AUTOSAR XML (schema 4-0-3)
standard types defined: Boolean, UInt16, UInt32
package /AUTOSAR_Platform/DataConstrs
  range DC_Boolean: raw 0..1
  range DC_UInt16: raw 0..65535
package /PATAC/Facility/DataTypes/Implementation
  compu method COMPU_Boolean: 0=FALSE, 1=TRUE
  unit NoUnit: factor-si-to-unit=1, offset-si-to-unit=0
package /PATAC/MSM/ComponentTypes
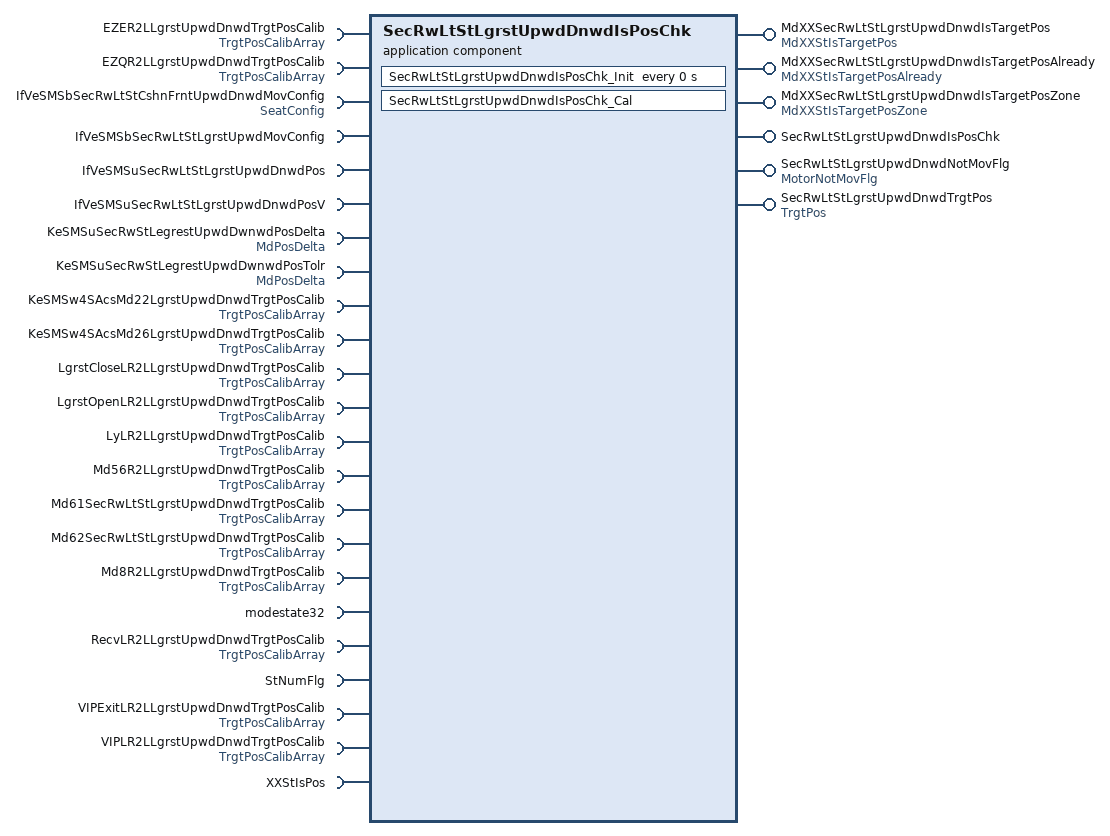
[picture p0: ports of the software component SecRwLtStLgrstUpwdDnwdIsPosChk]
  application sw component type SecRwLtStLgrstUpwdDnwdIsPosChk
    6 x provide port:
      MdXXSecRwLtStLgrstUpwdDnwdIsTargetPos: nonqueued-sender-com-spec=data-element=MdXXStIsTargetPos/Val, provided-interface=MdXXStIsTargetPos
      MdXXSecRwLtStLgrstUpwdDnwdIsTargetPosAlready: nonqueued-sender-com-spec=data-element=MdXXStIsTargetPosAlready/Val, provided-interface=MdXXStIsTargetPosAlready
      MdXXSecRwLtStLgrstUpwdDnwdIsTargetPosZone: nonqueued-sender-com-spec=data-element=MdXXStIsTargetPosZone/Val, provided-interface=MdXXStIsTargetPosZone
      SecRwLtStLgrstUpwdDnwdIsPosChk: server-com-spec{operation=Cal, queue-length=1}, provided-interface=SecRwLtStLgrstUpwdDnwdIsPosChk
      SecRwLtStLgrstUpwdDnwdNotMovFlg: nonqueued-sender-com-spec{data-element=MotorNotMovFlg/Val, init-value=0}, provided-interface=MotorNotMovFlg
      SecRwLtStLgrstUpwdDnwdTrgtPos: nonqueued-sender-com-spec{data-element=TrgtPos/Val, init-value=4095}, provided-interface=TrgtPos
    23 x require port:
      EZER2LLgrstUpwdDnwdTrgtPosCalib: nonqueued-receiver-com-spec{data-element=TrgtPosArray, filter=data-filter-type=ALWAYS, init-value=[4095, 4095, 4095]}, required-interface=TrgtPosCalibArray
      EZQR2LLgrstUpwdDnwdTrgtPosCalib: nonqueued-receiver-com-spec{data-element=TrgtPosArray, filter=data-filter-type=ALWAYS, init-value=[4095, 4095, 4095]}, required-interface=TrgtPosCalibArray
      IfVeSMSbSecRwLtStCshnFrntUpwdDnwdMovConfig: nonqueued-receiver-com-spec{data-element=SeatConfig/Val, filter=data-filter-type=ALWAYS, init-value=0}, required-interface=SeatConfig
      IfVeSMSbSecRwLtStLgrstUpwdMovConfig: nonqueued-receiver-com-spec{data-element=IfVeSMSbSecRwLtStLgrstUpwdMovConfig/Val, filter=data-filter-type=ALWAYS, init-value=0}, required-interface=IfVeSMSbSecRwLtStLgrstUpwdMovConfig
      IfVeSMSuSecRwLtStLgrstUpwdDnwdPos: nonqueued-receiver-com-spec{data-element=IfVeSMSuSecRwLtStLgrstUpwdDnwdPos/Val, filter=data-filter-type=ALWAYS, init-value=0}, required-interface=IfVeSMSuSecRwLtStLgrstUpwdDnwdPos
      IfVeSMSuSecRwLtStLgrstUpwdDnwdPosV: nonqueued-receiver-com-spec{data-element=IfVeSMSuSecRwLtStLgrstUpwdDnwdPosV/Val, filter=data-filter-type=ALWAYS, init-value=0}, required-interface=IfVeSMSuSecRwLtStLgrstUpwdDnwdPosV
      KeSMSuSecRwStLegrestUpwdDwnwdPosDelta: parameter-require-com-spec{init-value=150, parameter=Val}, required-interface=MdPosDelta
      KeSMSuSecRwStLegrestUpwdDwnwdPosTolr: parameter-require-com-spec{init-value=150, parameter=Val}, required-interface=MdPosDelta
      KeSMSw4SAcsMd22LgrstUpwdDnwdTrgtPosCalib: nonqueued-receiver-com-spec{data-element=TrgtPosArray, filter=data-filter-type=ALWAYS, init-value=[4095, 4095, 4095]}, required-interface=TrgtPosCalibArray
      KeSMSw4SAcsMd26LgrstUpwdDnwdTrgtPosCalib: nonqueued-receiver-com-spec{data-element=TrgtPosArray, filter=data-filter-type=ALWAYS, init-value=[4095, 4095, 4095]}, required-interface=TrgtPosCalibArray
      LgrstCloseLR2LLgrstUpwdDnwdTrgtPosCalib: nonqueued-receiver-com-spec{data-element=TrgtPosArray, filter=data-filter-type=ALWAYS, init-value=[4095, 4095, 4095]}, required-interface=TrgtPosCalibArray
      LgrstOpenLR2LLgrstUpwdDnwdTrgtPosCalib: nonqueued-receiver-com-spec{data-element=TrgtPosArray, filter=data-filter-type=ALWAYS, init-value=[4095, 4095, 4095]}, required-interface=TrgtPosCalibArray
      LyLR2LLgrstUpwdDnwdTrgtPosCalib: nonqueued-receiver-com-spec{data-element=TrgtPosArray, filter=data-filter-type=ALWAYS, init-value=[4095, 4095, 4095]}, required-interface=TrgtPosCalibArray
      Md56R2LLgrstUpwdDnwdTrgtPosCalib: nonqueued-receiver-com-spec{data-element=TrgtPosArray, filter=data-filter-type=ALWAYS, init-value=[4095, 4095, 4095]}, required-interface=TrgtPosCalibArray
      Md61SecRwLtStLgrstUpwdDnwdTrgtPosCalib: nonqueued-receiver-com-spec{data-element=TrgtPosArray, filter=data-filter-type=ALWAYS, init-value=[4095, 4095, 4095]}, required-interface=TrgtPosCalibArray
      Md62SecRwLtStLgrstUpwdDnwdTrgtPosCalib: nonqueued-receiver-com-spec{data-element=TrgtPosArray, filter=data-filter-type=ALWAYS, init-value=[4095, 4095, 4095]}, required-interface=TrgtPosCalibArray
      Md8R2LLgrstUpwdDnwdTrgtPosCalib: nonqueued-receiver-com-spec{data-element=TrgtPosArray, filter=data-filter-type=ALWAYS, init-value=[4095, 4095, 4095]}, required-interface=TrgtPosCalibArray
      modestate32: nonqueued-receiver-com-spec{data-element=modestate32/Val, filter=data-filter-type=ALWAYS, init-value=0}, required-interface=modestate32
      RecvLR2LLgrstUpwdDnwdTrgtPosCalib: nonqueued-receiver-com-spec{data-element=TrgtPosArray, filter=data-filter-type=ALWAYS, init-value=[4095, 4095, 4095]}, required-interface=TrgtPosCalibArray
      StNumFlg: required-interface=StNumFlg
        required-com-specs:
          data-element=Is4s, filter=data-filter-type=ALWAYS, init-value=0
          data-element=Is6s, filter=data-filter-type=ALWAYS, init-value=0
          data-element=Is6s7s, filter=data-filter-type=ALWAYS, init-value=0
          data-element=Is7s, filter=data-filter-type=ALWAYS, init-value=0
      VIPExitLR2LLgrstUpwdDnwdTrgtPosCalib: nonqueued-receiver-com-spec{data-element=TrgtPosArray, filter=data-filter-type=ALWAYS, init-value=[4095, 4095, 4095]}, required-interface=TrgtPosCalibArray
      VIPLR2LLgrstUpwdDnwdTrgtPosCalib: nonqueued-receiver-com-spec{data-element=TrgtPosArray, filter=data-filter-type=ALWAYS, init-value=[4095, 4095, 4095]}, required-interface=TrgtPosCalibArray
      XXStIsPos: client-com-spec=Get, required-interface=XXStIsPos
    behavior SecRwLtStLgrstUpwdDnwdIsPosChk_InternalBehavior
      operation invoked event OIT_SecRwLtStLgrstUpwdDnwdIsPosChk_Cal_SecRwLtStLgrstUpwdDnwdIsPosChk_Cal: start-on-event=SecRwLtStLgrstUpwdDnwdIsPosChk_Cal, operation=SecRwLtStLgrstUpwdDnwdIsPosChk.Cal
      timing event SecRwLtStLgrstUpwdDnwdIsPosChk_InitEvent: start-on-event=SecRwLtStLgrstUpwdDnwdIsPosChk_Init, period=0
      runnable SecRwLtStLgrstUpwdDnwdIsPosChk_Cal
        data-receive-point-by-arguments:
          23 x access:
            REC_EZER2LLgrstUpwdDnwdTrgtPosCalib_TrgtPosArray: accessed-variable=EZER2LLgrstUpwdDnwdTrgtPosCalib.TrgtPosArray
            REC_EZQR2LLgrstUpwdDnwdTrgtPosCalib_TrgtPosArray: accessed-variable=EZQR2LLgrstUpwdDnwdTrgtPosCalib.TrgtPosArray
            REC_IfVeSMSbSecRwLtStCshnFrntUpwdDnwdMovConfig_Val: accessed-variable=IfVeSMSbSecRwLtStCshnFrntUpwdDnwdMovConfig.Val
            REC_IfVeSMSbSecRwLtStLgrstUpwdMovConfig_Val: accessed-variable=IfVeSMSbSecRwLtStLgrstUpwdMovConfig.Val
            REC_IfVeSMSuSecRwLtStLgrstUpwdDnwdPos_Val: accessed-variable=IfVeSMSuSecRwLtStLgrstUpwdDnwdPos.Val
            REC_IfVeSMSuSecRwLtStLgrstUpwdDnwdPosV_Val: accessed-variable=IfVeSMSuSecRwLtStLgrstUpwdDnwdPosV.Val
            REC_KeSMSw4SAcsMd22LgrstUpwdDnwdTrgtPosCalib_TrgtPosArray: accessed-variable=KeSMSw4SAcsMd22LgrstUpwdDnwdTrgtPosCalib.TrgtPosArray
            REC_KeSMSw4SAcsMd26LgrstUpwdDnwdTrgtPosCalib_TrgtPosArray: accessed-variable=KeSMSw4SAcsMd26LgrstUpwdDnwdTrgtPosCalib.TrgtPosArray
            REC_LgrstCloseLR2LLgrstUpwdDnwdTrgtPosCalib_TrgtPosArray: accessed-variable=LgrstCloseLR2LLgrstUpwdDnwdTrgtPosCalib.TrgtPosArray
            REC_LgrstOpenLR2LLgrstUpwdDnwdTrgtPosCalib_TrgtPosArray: accessed-variable=LgrstOpenLR2LLgrstUpwdDnwdTrgtPosCalib.TrgtPosArray
            REC_LyLR2LLgrstUpwdDnwdTrgtPosCalib_TrgtPosArray: accessed-variable=LyLR2LLgrstUpwdDnwdTrgtPosCalib.TrgtPosArray
            REC_Md56R2LLgrstUpwdDnwdTrgtPosCalib_TrgtPosArray: accessed-variable=Md56R2LLgrstUpwdDnwdTrgtPosCalib.TrgtPosArray
            REC_Md61SecRwLtStLgrstUpwdDnwdTrgtPosCalib_TrgtPosArray: accessed-variable=Md61SecRwLtStLgrstUpwdDnwdTrgtPosCalib.TrgtPosArray
            REC_Md62SecRwLtStLgrstUpwdDnwdTrgtPosCalib_TrgtPosArray: accessed-variable=Md62SecRwLtStLgrstUpwdDnwdTrgtPosCalib.TrgtPosArray
            REC_Md8R2LLgrstUpwdDnwdTrgtPosCalib_TrgtPosArray: accessed-variable=Md8R2LLgrstUpwdDnwdTrgtPosCalib.TrgtPosArray
            REC_modestate32_Val: accessed-variable=modestate32.Val
            REC_RecvLR2LLgrstUpwdDnwdTrgtPosCalib_TrgtPosArray: accessed-variable=RecvLR2LLgrstUpwdDnwdTrgtPosCalib.TrgtPosArray
            REC_StNumFlg_Is4s: accessed-variable=StNumFlg.Is4s
            REC_StNumFlg_Is6s: accessed-variable=StNumFlg.Is6s
            REC_StNumFlg_Is6s7s: accessed-variable=StNumFlg.Is6s7s
            REC_StNumFlg_Is7s: accessed-variable=StNumFlg.Is7s
            REC_VIPExitLR2LLgrstUpwdDnwdTrgtPosCalib_TrgtPosArray: accessed-variable=VIPExitLR2LLgrstUpwdDnwdTrgtPosCalib.TrgtPosArray
            REC_VIPLR2LLgrstUpwdDnwdTrgtPosCalib_TrgtPosArray: accessed-variable=VIPLR2LLgrstUpwdDnwdTrgtPosCalib.TrgtPosArray
        data-send-points:
          5 x access:
            SEND_MdXXSecRwLtStLgrstUpwdDnwdIsTargetPos_Val: accessed-variable=MdXXSecRwLtStLgrstUpwdDnwdIsTargetPos.Val
            SEND_MdXXSecRwLtStLgrstUpwdDnwdIsTargetPosAlready_Val: accessed-variable=MdXXSecRwLtStLgrstUpwdDnwdIsTargetPosAlready.Val
            SEND_MdXXSecRwLtStLgrstUpwdDnwdIsTargetPosZone_Val: accessed-variable=MdXXSecRwLtStLgrstUpwdDnwdIsTargetPosZone.Val
            SEND_SecRwLtStLgrstUpwdDnwdNotMovFlg_Val: accessed-variable=SecRwLtStLgrstUpwdDnwdNotMovFlg.Val
            SEND_SecRwLtStLgrstUpwdDnwdTrgtPos_Val: accessed-variable=SecRwLtStLgrstUpwdDnwdTrgtPos.Val
        parameter access PA_KeSMSuSecRwStLegrestUpwdDwnwdPosDelta_Val: accessed-parameter=KeSMSuSecRwStLegrestUpwdDwnwdPosDelta.Val
        parameter access PA_KeSMSuSecRwStLegrestUpwdDwnwdPosTolr_Val: accessed-parameter=KeSMSuSecRwStLegrestUpwdDwnwdPosTolr.Val
        sync call SC_XXStIsPos_Get: operation=XXStIsPos.Get, timeout=0
      runnable SecRwLtStLgrstUpwdDnwdIsPosChk_Init
        parameter access PA_KeSMSuSecRwStLegrestUpwdDwnwdPosDelta_Val: accessed-parameter=KeSMSuSecRwStLegrestUpwdDwnwdPosDelta.Val
        parameter access PA_KeSMSuSecRwStLegrestUpwdDwnwdPosTolr_Val: accessed-parameter=KeSMSuSecRwStLegrestUpwdDwnwdPosTolr.Val
  swc implementation SecRwLtStLgrstUpwdDnwdIsPosChk_Implementation: behavior=SecRwLtStLgrstUpwdDnwdIsPosChk_InternalBehavior
    code-descriptors:
      code Default: artifact-descriptors=autosar-engineering-object={short-label=Default, category=SWSRC}
package /PATAC/MSM/ModeAdjust/CalPortInterface
  parameter interface MdPosDelta
    parameter data prototype Val: sw-calibration-access=READ-WRITE, type=UInt16
package /PATAC/MSM/ModeAdjust/DataType
  impl type TrgtPosCalibArray: category=ARRAY, sw-calibration-access=READ-ONLY, type-emitter=RTE  # 0:pos 1:max 2:min
    element Element: array-size=3, array-size-semantics=FIXED-SIZE, implementation-data-type=UInt16, invalid-value=0
package /PATAC/MSM/ModeAdjust/Interfaces
  sender receiver interface IfVeSMSuSecRwLtStLgrstUpwdDnwdPosV: invalidation-policy{data-element=IfVeSMSuSecRwLtStLgrstUpwdDnwdPosV/Val, handle-invalid=DONT-INVALIDATE}
    data Val: type=Implementation/Boolean
package /PATAC/MSM/ModeAdjust/PortInterface
  client server interface SecRwLtStLgrstUpwdDnwdIsPosChk
    operation Cal
  client server interface XXStIsPos
    operation Get
      8 x arg, all with server-argument-impl-policy=USE-ARGUMENT-TYPE:
        PosV: type=DataTypes/Boolean, direction=IN
        Pos: type=UInt16, direction=IN
        CalibArray: type=TrgtPosCalibArray, direction=IN
        Delta: type=UInt16, direction=IN
        Tolr: type=UInt16, direction=IN
        IsPos: type=DataTypes/Boolean, direction=OUT
        IsPosZone: type=DataTypes/Boolean, direction=OUT
        IsPosAlready: type=DataTypes/Boolean, direction=OUT
  7 x sender receiver interface:
    MdXXStIsTargetPos: invalidation-policy{data-element=MdXXStIsTargetPos/Val, handle-invalid=DONT-INVALIDATE}
      data Val: type=UInt32
    MdXXStIsTargetPosAlready: invalidation-policy{data-element=MdXXStIsTargetPosAlready/Val, handle-invalid=DONT-INVALIDATE}
      data Val: type=UInt32
    MdXXStIsTargetPosZone: invalidation-policy{data-element=MdXXStIsTargetPosZone/Val, handle-invalid=DONT-INVALIDATE}
      data Val: type=UInt32
    modestate32: invalidation-policy{data-element=modestate32/Val, handle-invalid=DONT-INVALIDATE}
      data Val: type=UInt32
    MotorNotMovFlg: invalidation-policy{data-element=MotorNotMovFlg/Val, handle-invalid=DONT-INVALIDATE}
      data Val: type=Implementation/Boolean
    StNumFlg
      4 x data, all with type=Implementation/Boolean:
        Is4s
        Is6s
        Is6s7s
        Is7s
      invalidation-policys:
        data-element=Is4s, handle-invalid=DONT-INVALIDATE
        data-element=Is6s, handle-invalid=DONT-INVALIDATE
        data-element=Is6s7s, handle-invalid=DONT-INVALIDATE
        data-element=Is7s, handle-invalid=DONT-INVALIDATE
    TrgtPosCalibArray: invalidation-policy{data-element=TrgtPosArray, handle-invalid=DONT-INVALIDATE}
      data TrgtPosArray: type=TrgtPosCalibArray  # 0:Pos 1:Max 2:Min
package /PATAC/MSM/PortInterfaces
  4 x sender receiver interface:
    IfVeSMSbSecRwLtStLgrstUpwdMovConfig: invalidation-policy{data-element=IfVeSMSbSecRwLtStLgrstUpwdMovConfig/Val, handle-invalid=DONT-INVALIDATE}
      data Val: type=Implementation/Boolean
    IfVeSMSuSecRwLtStLgrstUpwdDnwdPos: invalidation-policy{data-element=IfVeSMSuSecRwLtStLgrstUpwdDnwdPos/Val, handle-invalid=DONT-INVALIDATE}
      data Val: type=UInt16
    SeatConfig: invalidation-policy{data-element=SeatConfig/Val, handle-invalid=DONT-INVALIDATE}
      data Val: type=Implementation/Boolean
    TrgtPos: invalidation-policy{data-element=TrgtPos/Val, handle-invalid=DONT-INVALIDATE}
      data Val: type=UInt16
